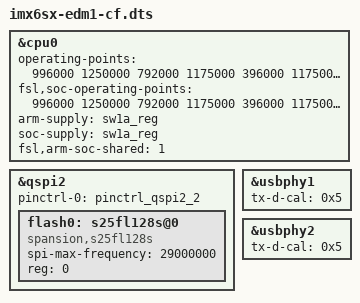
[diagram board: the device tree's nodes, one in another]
/*
 * Copyright (C) 2015 Freescale Semiconductor, Inc.
 * Copyright 2016 Technexion Ltd.
 *
 * Author: Richard Hu <richard.hu@technexion.com>
 *
 * This program is free software; you can redistribute it and/or modify
 * it under the terms of the GNU General Public License version 2 as
 * published by the Free Software Foundation.
 */

#include "imx6sx-edm1-cf.dtsi"

&cpu0 {
	operating-points = <
		/* kHz    uV */
		996000  1250000
		792000  1175000
		396000  1175000
		198000	1175000
		>;
	fsl,soc-operating-points = <
		/* ARM kHz      SOC uV */
		996000	1250000
		792000	1175000
		396000	1175000
		198000	1175000
	>;
	arm-supply = <&sw1a_reg>;
	soc-supply = <&sw1a_reg>;
	fsl,arm-soc-shared = <1>;
};

&qspi2 {
	pinctrl-names = "default";
	pinctrl-0 = <&pinctrl_qspi2_2>;
	status = "okay";

	flash0: s25fl128s@0 {
		#address-cells = <1>;
		#size-cells = <1>;
		compatible = "spansion,s25fl128s";
		spi-max-frequency = <29000000>;
		reg = <0>;
	};
};

&usbphy1 {
	tx-d-cal = <0x5>;
};

&usbphy2 {
	tx-d-cal = <0x5>;
};
